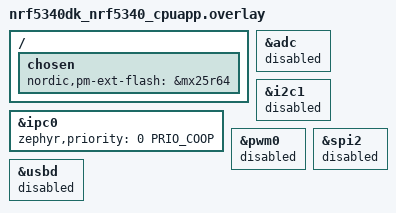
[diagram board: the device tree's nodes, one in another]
/*
 * Copyright (c) 2021 Nordic Semiconductor ASA
 *
 * SPDX-License-Identifier: LicenseRef-Nordic-5-Clause
 */

#include <zephyr/dt-bindings/ipc_service/static_vrings.h>

/ {
	chosen {
		nordic,pm-ext-flash = &mx25r64;
	};
};

/* Set IPC thread priority to the highest value to not collide with other threads. */
&ipc0 {
    zephyr,priority = <0 PRIO_COOP>;
};

/* Disable unused peripherals to reduce power consumption */
&adc {
	status = "disabled";
};
&i2c1 {
	status = "disabled";
};
&pwm0 {
	status = "disabled";
};
&spi2 {
	status = "disabled";
};
&usbd {
	status = "disabled";
};
